# DSS_EDP0_COMMON_0_V2A_CORE_VP_REGS_APB register map
Vendor: Texas Instruments
Registers are 32-bit, access not given, reset 0x0 unless marked. A register's access mark holds for its fields unless they carry their own. Offsets are as the file gives them; [hi:lo] are bit positions; {n}, {i} and the like mark numbered series; 'fields as' and 'values as' point back to an identical list.

## DSS_EDP0_COMMON_0_V2A_CORE_VP_REGS_APB (part 2 of 3)
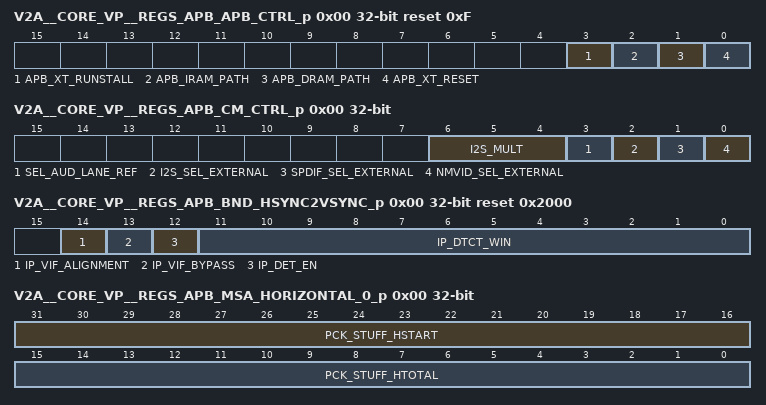
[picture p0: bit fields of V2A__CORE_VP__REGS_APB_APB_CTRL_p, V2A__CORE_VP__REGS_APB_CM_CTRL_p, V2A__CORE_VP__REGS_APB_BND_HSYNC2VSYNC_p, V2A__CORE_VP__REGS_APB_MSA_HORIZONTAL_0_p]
0x00 V2A__CORE_VP__REGS_APB_APB_CTRL_p reset 0xF
  [3] APB_XT_RUNSTALL rw — When 1 stalls the CPU from executing further instructions. This bit must be set HIGH during firmware load.
  [2] APB_IRAM_PATH rw — Unused. Kept RW for software backward compatibility.
  [1] APB_DRAM_PATH rw — Unused. Kept RW for software backward compatibility.
  [0] APB_XT_RESET rw — Internal uCPU reset. Active High. Must be cleared to enable firmware load and normal operation of the uCPU.
0x00 V2A__CORE_VP__REGS_APB_CM_CTRL_p
  [6:4] I2S_MULT rw — Select the division of N value for different I2S TDM configuration
  [3] SEL_AUD_LANE_REF rw — When 1 Select Audio CLK as a reference [HDMI] When 0 Select LANE CLK as a reference [DP]
  [2] I2S_SEL_EXTERNAL rw — When 1 Select external values of NMAUD [N/A] for I2S
  [1] SPDIF_SEL_EXTERNAL rw — When 1 Select external values of NMAUD [N/A] for SPDIF
  [0] NMVID_SEL_EXTERNAL rw — When 1 Select external values of NMVID [N/A]
0x00 V2A__CORE_VP__REGS_APB_CM_CTRL_p
  fields as V2A__CORE_VP__REGS_APB_CM_CTRL_p
0x00 V2A__CORE_VP__REGS_APB_BND_HSYNC2VSYNC_p reset 0x2000
  [14] IP_VIF_ALIGNMENT rw — Alignment of the input pixel data at the pixel interface: 0-MSB alignment 1-LSB alignment.
  [13] IP_VIF_BYPASS rw — Bypass video interface.
  [12] IP_DET_EN rw — Enable detection of Interlace formats after decided if the polarity is Automatic or Manual detection.
  [11:0] IP_DTCT_WIN rw — Bound for HSYNC to VSYNC for all fields.
0x00 V2A__CORE_VP__REGS_APB_MSA_HORIZONTAL_0_p rw
  [31:16] PCK_STUFF_HSTART — MSA Hstart value. Horizontal active start from leading edge of Hsync, measured in pixel count.
  [15:0] PCK_STUFF_HTOTAL — MSA HTotal value. Horizontal total of transmitted main video stream, measured in pixel count.
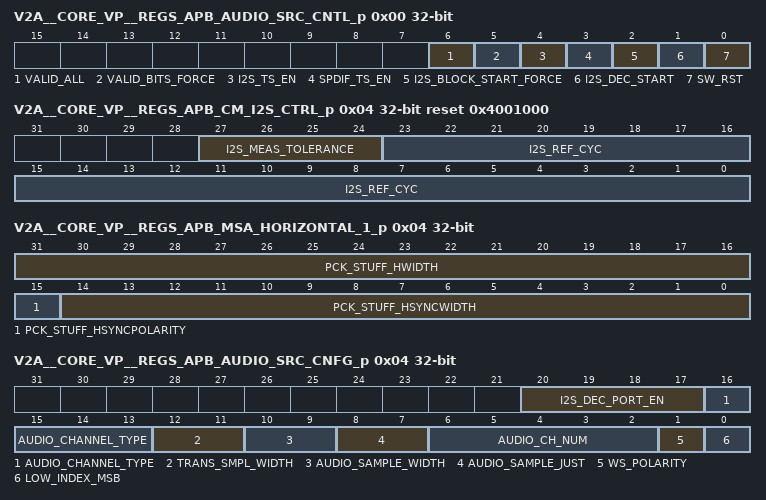
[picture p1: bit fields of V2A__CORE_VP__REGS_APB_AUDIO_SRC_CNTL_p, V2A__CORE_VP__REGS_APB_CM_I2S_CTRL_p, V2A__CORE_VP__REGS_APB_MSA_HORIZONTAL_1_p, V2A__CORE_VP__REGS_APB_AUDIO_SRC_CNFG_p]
0x00 V2A__CORE_VP__REGS_APB_AUDIO_SRC_CNTL_p
  [6] VALID_ALL rw — valid bit for all samples
  [5] VALID_BITS_FORCE rw — Force valid bits of the channels
  [4] I2S_TS_EN rw — Enable I2S Time Stamp when decoders are disabled
  [3] SPDIF_TS_EN rw — Enable SPDIF Time Stamp when decoders are disabled
  [2] I2S_BLOCK_START_FORCE rw — Force a Block Start in the audio stream
  [1] I2S_DEC_START rw — When high Source Decoder starts.
  [0] SW_RST rw — Software reset. Active high.
0x00 V2A__CORE_VP__REGS_APB_SOURCE_PIF_WR_ADDR_p
  [3:0] WR_ADDR rw — 4 MSB of the packet memory address in which the data is written.
0x04 V2A__CORE_VP__REGS_APB_xt_int_ctrl_p
  [1:0] XT_INT_POLARITY rw — Each bit inverts appropriate interrupt signal provided do internal CPU interrupt input.
0x04 V2A__CORE_VP__REGS_APB_CM_I2S_CTRL_p reset 0x4001000
  [27:24] I2S_MEAS_TOLERANCE rw — Measurement tolerance of Audio clock to be stable in clocks
  [23:0] I2S_REF_CYC rw — Reference cycles for I2S Audio meter
0x04 V2A__CORE_VP__REGS_APB_HSYNC2VSYNC_F1_L1_p
  [15:0] IP_DTCT_HSYNC2VSYNC_F1 ro — Value of HSYNC to VSYNC field 1.
0x04 V2A__CORE_VP__REGS_APB_MSA_HORIZONTAL_1_p rw
  [31:16] PCK_STUFF_HWIDTH — MSA Hwidth parameter. Active video width, measured in pixel count.
  [15] PCK_STUFF_HSYNCPOLARITY — MSA HSync Polarity. 0 - Active high pulse. Synchronization signal is high for the sync pulse width. 1 - Active low pulse. Synchronization signal is low for the sync pulse width. This value may be different than actual polarity of the stream received at the video input interface.
  [14:0] PCK_STUFF_HSYNCWIDTH — MSA HSyncWidth parameter. Hsync width, measured in pixel count.
0x04 V2A__CORE_VP__REGS_APB_AUDIO_SRC_CNFG_p
  [20:17] I2S_DEC_PORT_EN rw — Enables the I2S Decoder ports. Allowed values are: 0001 - I2S port 0 is enabled. 0011 - I2S ports 0,1 are enabled. 1111 - I2S ports 0,1,2,3 are enabled. No other values are allowed.
  [16:13] AUDIO_CHANNEL_TYPE rw — Set the transmission type.
  [12:11] TRANS_SMPL_WIDTH rw — Decoder Word Select width: 00-16 bit 01-24 bit 10-32 bit
  [10:9] AUDIO_SAMPLE_WIDTH rw — Decoder sample width: 00-16 bit 01-24 bit 10-32 bit
  [8:7] AUDIO_SAMPLE_JUST rw — Data justification setting: 00 left-justified 01 right-justified
  [6:2] AUDIO_CH_NUM rw — Number of channels to decode
  [1] WS_POLARITY rw — Word Select Polarity. 0: No change 1: Inverted.
  [0] LOW_INDEX_MSB rw — When low MSB is transmitted first. When high LSB is transmitted first.
0x04 V2A__CORE_VP__REGS_APB_SOURCE_PIF_WR_REQ_p
  [0] HOST_WR rw — Write request bit for the host write transaction, active high. Bit is automatically cleared when operation is completed.
0x08 V2A__CORE_VP__REGS_APB_MAILBOX_FULL_ADDR_p
  [0] MAILBOX_FULL ro — Mailbox full indication. 0x1-mailbox full. No more messages can be sent to mailbox 0x0-mailbox not-full. At least 1 write can be performed to mailbox
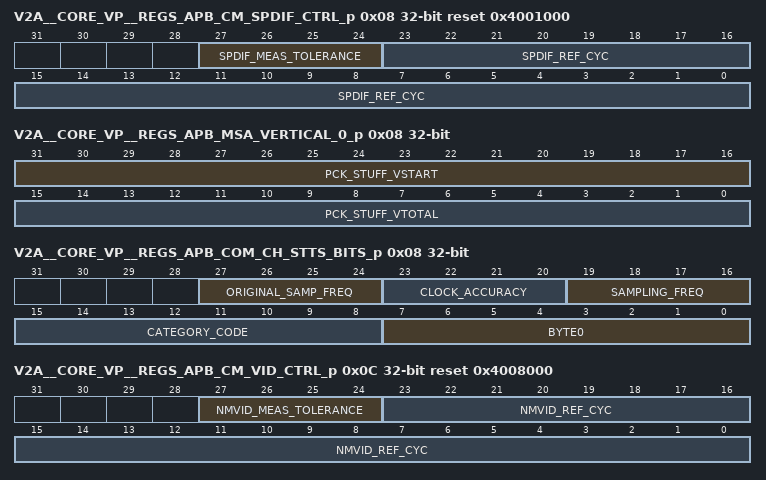
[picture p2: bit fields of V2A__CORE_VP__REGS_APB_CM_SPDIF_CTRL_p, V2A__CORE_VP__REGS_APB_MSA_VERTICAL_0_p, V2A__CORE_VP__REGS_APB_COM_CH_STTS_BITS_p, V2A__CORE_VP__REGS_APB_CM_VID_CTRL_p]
0x08 V2A__CORE_VP__REGS_APB_CM_SPDIF_CTRL_p reset 0x4001000
  [27:24] SPDIF_MEAS_TOLERANCE rw — SPDIF measurement tolerance to be stable in clocks
  [23:0] SPDIF_REF_CYC rw — Reference cycles of SPDIF measurement
0x08 V2A__CORE_VP__REGS_APB_HSYNC2VSYNC_F2_L1_p
  [15:0] IP_DTCT_HSYNC2VSYNC_F2 ro — Value of HSYNC to VSYNC field 2.
0x08 V2A__CORE_VP__REGS_APB_MSA_VERTICAL_0_p rw
  [31:16] PCK_STUFF_VSTART — MSA Vstart parameter. Vertical active start from leading edge of Vsync, measured in line count.
  [15:0] PCK_STUFF_VTOTAL — MSA Vtotal parameter. Vertical total of transmitted main video stream, measured in line count.
0x08 V2A__CORE_VP__REGS_APB_COM_CH_STTS_BITS_p
  [27:24] ORIGINAL_SAMP_FREQ rw — Original Sampling Freq. of transmitted channel. Same for all channels.
  [23:20] CLOCK_ACCURACY rw — Clock Accuracy of transmitted channel. Same for all channels.
  [19:16] SAMPLING_FREQ rw — Sampling Frequency of transmitted channel. Same for all channels.
  [15:8] CATEGORY_CODE rw — Category Code of transmitted channel. Same for all channels.
  [7:0] BYTE0 rw — Byte 0 of transmitted channel. Same for all channels.
0x08 V2A__CORE_VP__REGS_APB_SOURCE_PIF_RD_ADDR_p
  [3:0] RD_ADDR rw — 4 MSB of the packet memory address from which the data is read.
0x0C V2A__CORE_VP__REGS_APB_MAILBOX_EMPTY_ADDR_p reset 0x1
  [0] MAILBOX_EMPTY ro — Mailbox empty indication. 0x1-mailbox empty. No response available 0x0-mailbox not-empty. There is at least 1 byte of a response in mailbox available to read by Host processor
0x0C V2A__CORE_VP__REGS_APB_CM_VID_CTRL_p reset 0x4008000
  [27:24] NMVID_MEAS_TOLERANCE rw — Video measurement tolerance in pixel clock cycles
  [23:0] NMVID_REF_CYC rw — Video Reference cycles
0x0C V2A__CORE_VP__REGS_APB_CM_VID_CTRL_p reset 0x4008000
  fields as V2A__CORE_VP__REGS_APB_CM_VID_CTRL_p
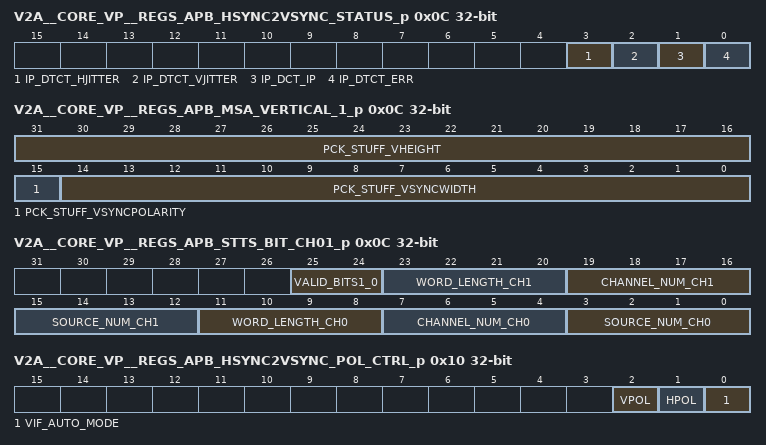
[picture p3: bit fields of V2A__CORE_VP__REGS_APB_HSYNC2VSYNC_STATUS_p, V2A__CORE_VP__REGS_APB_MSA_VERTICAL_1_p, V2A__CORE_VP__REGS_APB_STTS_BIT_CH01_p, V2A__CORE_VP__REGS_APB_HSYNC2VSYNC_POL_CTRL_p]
0x0C V2A__CORE_VP__REGS_APB_HSYNC2VSYNC_STATUS_p
  [3] IP_DTCT_HJITTER ro — Asserted when jitter is observed on htotal i.e. HSYNC rising edge to next HSYNC rising edge delay count. Clear on Read.
  [2] IP_DTCT_VJITTER ro — Asserted when jitter is observed on vtotal i.e. VSYNC rising edge to next VSYNC rising edge delay count. Clear on Read.
  [1] IP_DCT_IP ro — When asserted interlaced format is detected else progressive format.
  [0] IP_DTCT_ERR ro — Asserted when HSYNC to VSYNC bound is violated. Clear on Read.
0x0C V2A__CORE_VP__REGS_APB_MSA_VERTICAL_1_p rw
  [31:16] PCK_STUFF_VHEIGHT — MSA VHeigh parameter. Active video height, measured in line count.
  [15] PCK_STUFF_VSYNCPOLARITY — MSA VSyncPolarity. 0 - Active high pulse. Synchronization signal is high for the sync pulse width. 1 - Active low pulse. Synchronization signal is low for the sync pulse width. This value may be different than actual polarity of the stream received at the video input interface.
  [14:0] PCK_STUFF_VSYNCWIDTH — MSA VSyncWidth parameter. Vsync width, measured in line count.
0x0C V2A__CORE_VP__REGS_APB_STTS_BIT_CH01_p
  [25:24] VALID_BITS1_0 rw — Valid Bits for channel 1 and 0 if force is enabled
  [23:20] WORD_LENGTH_CH1 rw — Channel 1 word length.
  [19:16] CHANNEL_NUM_CH1 rw — Channel 1 channel number.
  [15:12] SOURCE_NUM_CH1 rw — Channel 1 Source number.
  [11:8] WORD_LENGTH_CH0 rw — Channel 0 word length.
  [7:4] CHANNEL_NUM_CH0 rw — Channel 0 channel number.
  [3:0] SOURCE_NUM_CH0 rw — Channel 0 Source number.
0x0C V2A__CORE_VP__REGS_APB_SOURCE_PIF_RD_REQ_p
  [0] HOST_RD rw — Read request bit for the host read transaction, active high. Bit is automatically cleared when operation is completed.
0x10 V2A__CORE_VP__REGS_APB_mailbox0_wr_data_p
  [7:0] MAILBOX0_WR_DATA rw — Mailbox write data.
0x10 V2A__CORE_VP__REGS_APB_CM_LANE_CTRL_p
  [23:0] LANE_REF_CYC rw — Reference cycles when using lane clock as Reference [DP]
0x10 V2A__CORE_VP__REGS_APB_HSYNC2VSYNC_POL_CTRL_p
  [2] VPOL rw — VSYNC polarity: 0-active HIGH 1-active LOW.
  [1] HPOL rw — HSYNC polarity: 0-active HIGH 1-active LOW.
  [0] VIF_AUTO_MODE rw — Automatic or Manual configuration of the polarity: 0-vpol and hpol settings are used 1-automatic detection of polarity of input VSYNC and HSYNC
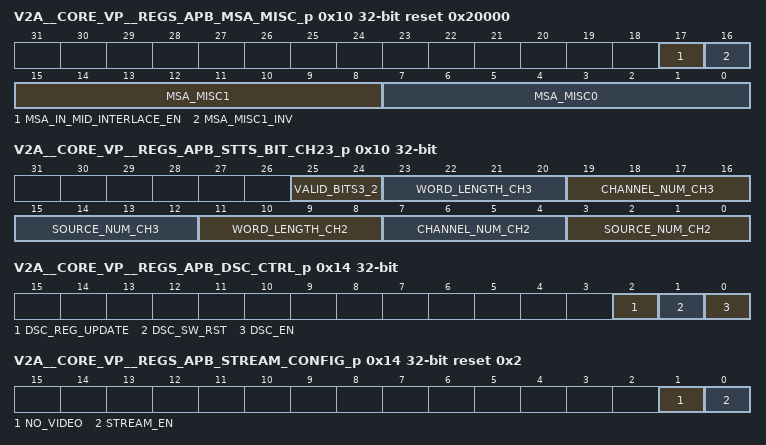
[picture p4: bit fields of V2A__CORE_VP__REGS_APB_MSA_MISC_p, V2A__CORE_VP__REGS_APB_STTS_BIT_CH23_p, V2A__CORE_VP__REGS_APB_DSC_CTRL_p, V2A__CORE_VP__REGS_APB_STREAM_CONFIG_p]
0x10 V2A__CORE_VP__REGS_APB_MSA_MISC_p reset 0x20000
  [17] MSA_IN_MID_INTERLACE_EN rw — MSA transmission control in interlaced mode. 0 - enable transmission of MSA on each field, 1 - MSA transmitted on Top only
  [16] MSA_MISC1_INV rw — L/R toggle for interlaced and field sequential video. 0 - left 1 - right
  [15:8] MSA_MISC1 rw — MAS Miscellaneous1 as described in DisplayPort specification.
  [7:0] MSA_MISC0 rw — MSA Miscellaneous0 as described in DisplayPort specification.
0x10 V2A__CORE_VP__REGS_APB_STTS_BIT_CH23_p
  [25:24] VALID_BITS3_2 rw — Valid Bits for channel 3 and 2 if force is enabled
  [23:20] WORD_LENGTH_CH3 rw — Channel 3 word length.
  [19:16] CHANNEL_NUM_CH3 rw — Channel 3 channel number.
  [15:12] SOURCE_NUM_CH3 rw — Channel 3 Source number.
  [11:8] WORD_LENGTH_CH2 rw — Channel 2 word length.
  [7:4] CHANNEL_NUM_CH2 rw — Channel 2 channel number.
  [3:0] SOURCE_NUM_CH2 rw — Channel 2 Source number.
0x10 V2A__CORE_VP__REGS_APB_SOURCE_PIF_DATA_WR_p rw
  [31:0] DATA_WR — The 32 bits of the data to be written to the packet memory. When written to this register fifo1_wr_enable will automatically be asserted and the data is stored in FIFO.
0x14 V2A__CORE_VP__REGS_APB_mailbox0_rd_data_p
  [7:0] MAILBOX0_RD_DATA ro — Mailbox Read data.
0x14 V2A__CORE_VP__REGS_APB_I2S_NM_STABLE_p
  [0] I2S_MNAUD_STABLE ro — I2S NMAUD Mesurment stable
0x14 V2A__CORE_VP__REGS_APB_DSC_CTRL_p
  [2] DSC_REG_UPDATE rw — DSC registers update: active HIGH.
  [1] DSC_SW_RST rw — DSC software reset: active HIGH.
  [0] DSC_EN rw — DSC enable bit: 1-DSC is enabled 0-DSC is disabled
0x14 V2A__CORE_VP__REGS_APB_STREAM_CONFIG_p reset 0x2
  [1] NO_VIDEO rw — Stream no video mode. 0 - video mode 1 - no video mode
  [0] STREAM_EN rw — Stream enable. 0 - stream disabled 1 - stream enabled
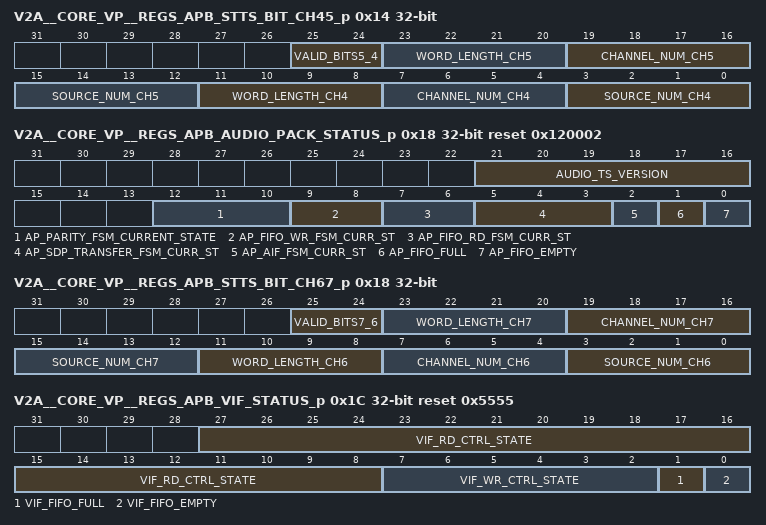
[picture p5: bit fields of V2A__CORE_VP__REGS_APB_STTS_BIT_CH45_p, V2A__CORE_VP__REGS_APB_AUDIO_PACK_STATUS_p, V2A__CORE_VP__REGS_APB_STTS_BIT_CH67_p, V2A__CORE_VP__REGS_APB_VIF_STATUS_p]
0x14 V2A__CORE_VP__REGS_APB_STTS_BIT_CH45_p
  [25:24] VALID_BITS5_4 rw — Valid Bits for channel 5 and 4 if force is enabled
  [23:20] WORD_LENGTH_CH5 rw — Channel 5 word length.
  [19:16] CHANNEL_NUM_CH5 rw — Channel 5 channel number.
  [15:12] SOURCE_NUM_CH5 rw — Channel 5 Source number.
  [11:8] WORD_LENGTH_CH4 rw — Channel 4 word length.
  [7:4] CHANNEL_NUM_CH4 rw — Channel 4 channel number.
  [3:0] SOURCE_NUM_CH4 rw — Channel 4 Source number.
0x14 V2A__CORE_VP__REGS_APB_SOURCE_PIF_DATA_RD_p ro
  [31:0] FIFO2_DATA_OUT — The 32 bits of the data to be read from the packet memory. When read from this register fifo2_rd_enable will automatically be asserted and the data is read from the FIFO.
0x18 V2A__CORE_VP__REGS_APB_KEEP_ALIVE_p
  [7:0] KEEP_ALIVE_CNT ro — Software keep alive counter. Counter is initialized to 0x0 after reset and incremented by 0x1 with every FW kernel loop. It can be used to determine if internal CPU started running correctly.
0x18 V2A__CORE_VP__REGS_APB_I2S_NCTS_STABLE_p
  [0] I2S_NCTS_STABLE ro — i2s CTS measurement stable
0x18 V2A__CORE_VP__REGS_APB_AUDIO_PACK_STATUS_p reset 0x120002
  [21:16] AUDIO_TS_VERSION rw — Audio timestamp version. This field is transmitted in HB3[7:2] of a Audio_TimeStamp SDP Header.
  [12:10] AP_PARITY_FSM_CURRENT_STATE ro — Audio pack parity calc fsm state. Used only for debug purposes.
  [9:8] AP_FIFO_WR_FSM_CURR_ST ro — Audio pack FIFO write fsm state. Used only for debug purposes.
  [7:6] AP_FIFO_RD_FSM_CURR_ST ro — Audio pack FIFO read fsm state. Used only for debug purposes.
  [5:3] AP_SDP_TRANSFER_FSM_CURR_ST ro — Audio pack sdp transfer fsm state. Used only for debug purposes.
  [2] AP_AIF_FSM_CURR_ST ro — Audio pack aif fsm state. Used only for debug purposes.
  [1] AP_FIFO_FULL ro — Audio Pack Sync FIFO full flag, active high. Used only for debug purposes.
  [0] AP_FIFO_EMPTY ro — Audio Pack Sync FIFO empty flag, active high. Used only for debug purposes.
0x18 V2A__CORE_VP__REGS_APB_STTS_BIT_CH67_p
  [25:24] VALID_BITS7_6 rw — Valid Bits for channel 7 and 6 if force is enabled
  [23:20] WORD_LENGTH_CH7 rw — Channel 7 word length.
  [19:16] CHANNEL_NUM_CH7 rw — Channel 7 channel number.
  [15:12] SOURCE_NUM_CH7 rw — Channel 7 Source number.
  [11:8] WORD_LENGTH_CH6 rw — Channel 6 word length.
  [7:4] CHANNEL_NUM_CH6 rw — Channel 6 channel number.
  [3:0] SOURCE_NUM_CH6 rw — Channel 6 Source number.
0x18 V2A__CORE_VP__REGS_APB_SOURCE_PIF_FIFO1_FLUSH_p
  [0] FIFO1_FLUSH rw — Fifo1 flush bit, active high. Bit is automatically cleared when operation is completed.
0x1C V2A__CORE_VP__REGS_APB_VER_L_p
  [7:0] VER_LSB ro — Software Version lower byte. Loaded by Firmware at the beginning of firmware operation.
0x1C V2A__CORE_VP__REGS_APB_SPDIF_NM_STABLE_p
  [0] SPDIF_MNAUD_STABLE ro — SPDIF NMAUD measurement stable
0x1C V2A__CORE_VP__REGS_APB_VIF_STATUS_p reset 0x5555
  [27:8] VIF_RD_CTRL_STATE ro — VIF rd fsm current state.
  [7:2] VIF_WR_CTRL_STATE ro — VIF wr fsm current state.
  [1] VIF_FIFO_FULL ro — VIF ASync FIFO full flag, active high.
  [0] VIF_FIFO_EMPTY ro — VIF ASync FIFO empty flag, active high.
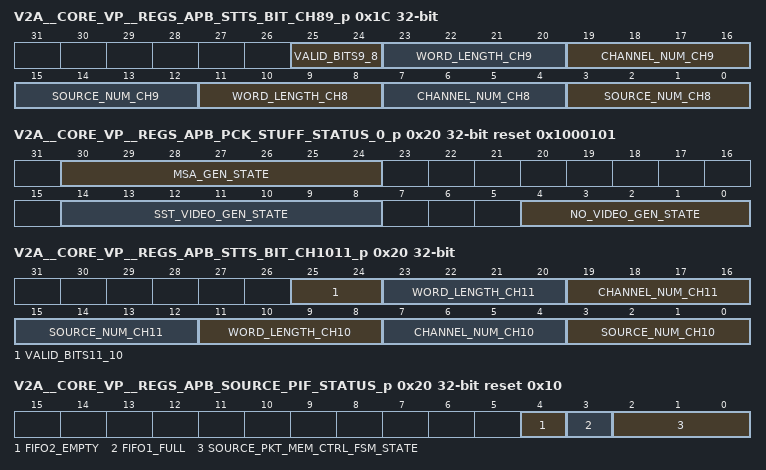
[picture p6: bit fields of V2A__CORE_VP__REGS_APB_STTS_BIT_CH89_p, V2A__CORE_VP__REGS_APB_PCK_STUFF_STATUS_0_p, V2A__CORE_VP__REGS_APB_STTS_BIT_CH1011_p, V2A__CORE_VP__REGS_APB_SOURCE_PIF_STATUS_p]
0x1C V2A__CORE_VP__REGS_APB_STTS_BIT_CH89_p
  [25:24] VALID_BITS9_8 rw — Valid Bits for channel 9 and 8 if force is enabled
  [23:20] WORD_LENGTH_CH9 rw — Channel 9 word length.
  [19:16] CHANNEL_NUM_CH9 rw — Channel 9 channel number.
  [15:12] SOURCE_NUM_CH9 rw — Channel 9 Source number.
  [11:8] WORD_LENGTH_CH8 rw — Channel 8 word length.
  [7:4] CHANNEL_NUM_CH8 rw — Channel 8 channel number.
  [3:0] SOURCE_NUM_CH8 rw — Channel 8 Source number.
0x1C V2A__CORE_VP__REGS_APB_SOURCE_PIF_FIFO2_FLUSH_p
  [0] FIFO2_FLUSH rw — Fifo2 flush bit, active high. Bit is automatically cleared when operation is completed.
0x20 V2A__CORE_VP__REGS_APB_VER_H_p
  [7:0] VER_MSB ro — Software Version higher byte. Loaded by Firmware at the beginning of firmware operation.
0x20 V2A__CORE_VP__REGS_APB_SPDIF_NCTS_STABLE_p
  [0] SPDIF_NCTS_STABLE ro — SPDIF CTS measurement stable
0x20 V2A__CORE_VP__REGS_APB_PCK_STUFF_STATUS_0_p reset 0x1000101
  [30:24] MSA_GEN_STATE ro — Secondary Data generator FSM status.
  [14:8] SST_VIDEO_GEN_STATE ro — SST video generator FSM status.
  [4:0] NO_VIDEO_GEN_STATE ro — No video generator FSM status.
0x20 V2A__CORE_VP__REGS_APB_STTS_BIT_CH1011_p
  [25:24] VALID_BITS11_10 rw — Valid Bits for channel 11 and 10 if force is enabled
  [23:20] WORD_LENGTH_CH11 rw — Channel 11 word length.
  [19:16] CHANNEL_NUM_CH11 rw — Channel 11 channel number.
  [15:12] SOURCE_NUM_CH11 rw — Channel 11 Source number.
  [11:8] WORD_LENGTH_CH10 rw — Channel 10 word length.
  [7:4] CHANNEL_NUM_CH10 rw — Channel 10 channel number.
  [3:0] SOURCE_NUM_CH10 rw — Channel 10 Source number.
0x20 V2A__CORE_VP__REGS_APB_SOURCE_PIF_STATUS_p reset 0x10
  [4] FIFO2_EMPTY ro — Fifo2 empty indication, when high indicates that FIFO2 is empty
  [3] FIFO1_FULL ro — Fifo1 full indication, when high indicates that FIFO1 is full
  [2:0] SOURCE_PKT_MEM_CTRL_FSM_STATE ro — State of the FSM that controls packet memory transactions.
0x24 V2A__CORE_VP__REGS_APB_VER_LIB_L_ADDR_p
  [7:0] SW_LIB_VER_L ro — Software Library Version lower byte. Loaded by Firmware at the beginning of firmware operation.
0x24 V2A__CORE_VP__REGS_APB_NMVID_MEAS_STABLE_p
  [0] ST_NMVID_MEAS_STABLE ro — Pixel clock NMVID measurement stable
0x24 V2A__CORE_VP__REGS_APB_NMVID_MEAS_STABLE_p
  [0] ST_NMVID_MEAS_STABLE ro — Pixel clock NMVID measurement stable
0x24 V2A__CORE_VP__REGS_APB_PCK_STUFF_STATUS_1_p reset 0x1
  [5:0] SST_SS_GEN_STATE ro — MSA generator FSM status.
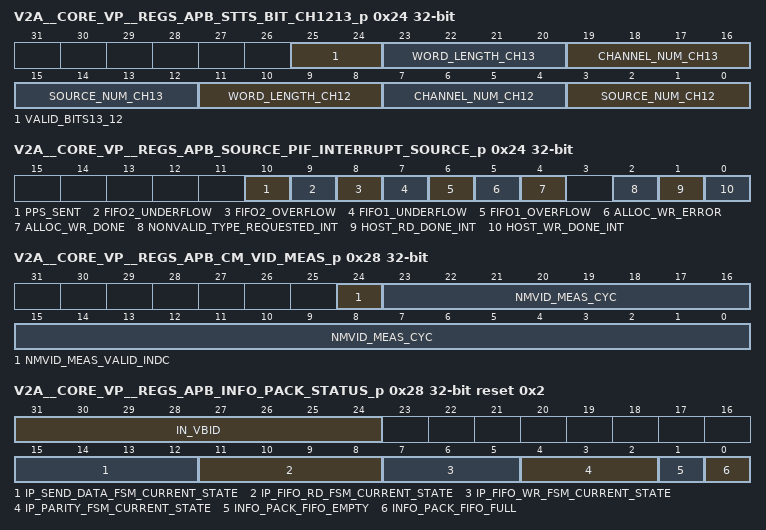
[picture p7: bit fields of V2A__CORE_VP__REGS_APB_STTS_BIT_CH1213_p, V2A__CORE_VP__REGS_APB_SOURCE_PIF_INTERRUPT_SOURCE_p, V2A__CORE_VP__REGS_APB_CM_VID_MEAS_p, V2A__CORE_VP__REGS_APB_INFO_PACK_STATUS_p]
0x24 V2A__CORE_VP__REGS_APB_STTS_BIT_CH1213_p
  [25:24] VALID_BITS13_12 rw — Valid Bits for channel 13 and 12 if force is enabled
  [23:20] WORD_LENGTH_CH13 rw — Channel 13 word length.
  [19:16] CHANNEL_NUM_CH13 rw — Channel 13 channel number.
  [15:12] SOURCE_NUM_CH13 rw — Channel 13 Source number.
  [11:8] WORD_LENGTH_CH12 rw — Channel 12 word length.
  [7:4] CHANNEL_NUM_CH12 rw — Channel 12 channel number.
  [3:0] SOURCE_NUM_CH12 rw — Channel 12 Source number.
0x24 V2A__CORE_VP__REGS_APB_SOURCE_PIF_INTERRUPT_SOURCE_p
  [10] PPS_SENT ro — PPS sent to framer indication. Active HIGH. Clear on read.
  [9] FIFO2_UNDERFLOW ro — Fifo2 underflow indication. Indicates incorrect programming sequence. Active HIGH. Clear on read.
  [8] FIFO2_OVERFLOW ro — Fifo2 overflow indication. Indicates incorrect programming sequence. Active HIGH. Clear on read.
  [7] FIFO1_UNDERFLOW ro — Fifo1 underflow indication. Indicates incorrect programming sequence. Active HIGH. Clear on read.
  [6] FIFO1_OVERFLOW ro — Fifo1 overflow indication. Indicates incorrect programming sequence. Active HIGH. Clear on read.
  [5] ALLOC_WR_ERROR ro — Error happened, invalid write to the allocation table. Indicates incorrect programming sequence. Active HIGH. Clear on read.
  [4] ALLOC_WR_DONE ro — Successful write to the allocation table. Active HIGH. Clear on read.
  [2] NONVALID_TYPE_REQUESTED_INT ro — Indication that nonvalid type of packet is requested by the packet interface. Indicates incorrect programming sequence. Active HIGH. Clear on read.
  [1] HOST_RD_DONE_INT ro — Indication that the host read transaction finished. Active HIGH. Clear on read.
  [0] HOST_WR_DONE_INT ro — Indication that the host write transaction finished. Active HIGH. Clear on read.
0x28 V2A__CORE_VP__REGS_APB_VER_LIB_H_ADDR_p
  [7:0] SW_LIB_VER_H ro — Software Library Version higher byte. Loaded by Firmware at the beginning of firmware operation.
0x28 V2A__CORE_VP__REGS_APB_CM_VID_MEAS_p
  [24] NMVID_MEAS_VALID_INDC rw — When Toggle Valid pulse is generated to sample MNVID fix value
  [23:0] NMVID_MEAS_CYC rw — Fixed Value for NVID , The MVID is nmvid_ref_cyc[23:0]
0x28 V2A__CORE_VP__REGS_APB_CM_VID_MEAS_p
  fields as V2A__CORE_VP__REGS_APB_CM_VID_MEAS_p
0x28 V2A__CORE_VP__REGS_APB_INFO_PACK_STATUS_p reset 0x2
  [31:24] IN_VBID ro — Value of the sent VB-ID [vb_id_final].
  [15:12] IP_SEND_DATA_FSM_CURRENT_STATE ro — State of the send_data FSM.
  [11:8] IP_FIFO_RD_FSM_CURRENT_STATE ro — State of the fifo_rd FSM.
  [7:5] IP_FIFO_WR_FSM_CURRENT_STATE ro — State of the fifo_wr FSM.
  [4:2] IP_PARITY_FSM_CURRENT_STATE ro — State of the parity FSM.
  [1] INFO_PACK_FIFO_EMPTY ro — Info_pack fifo empty flag, active high.
  [0] INFO_PACK_FIFO_FULL ro — Info_pack fifo full flag, active high.
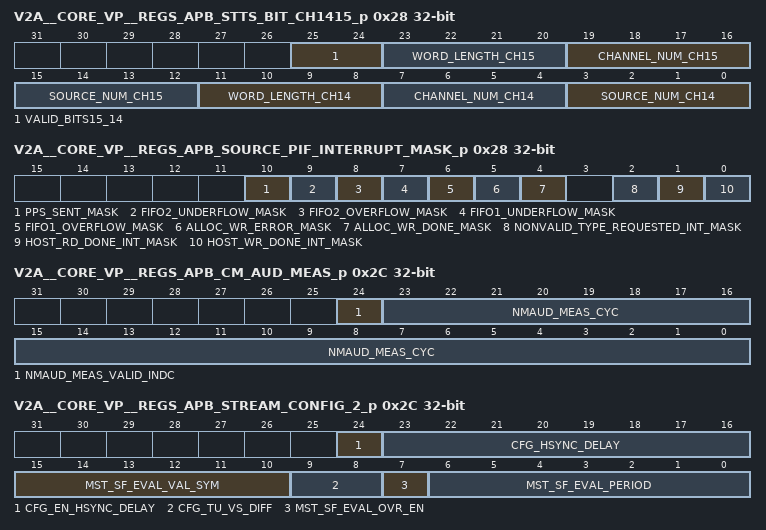
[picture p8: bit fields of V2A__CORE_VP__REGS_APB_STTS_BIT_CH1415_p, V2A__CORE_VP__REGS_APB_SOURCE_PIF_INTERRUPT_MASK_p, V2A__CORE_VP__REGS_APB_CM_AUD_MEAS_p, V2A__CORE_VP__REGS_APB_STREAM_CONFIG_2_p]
0x28 V2A__CORE_VP__REGS_APB_STTS_BIT_CH1415_p
  [25:24] VALID_BITS15_14 rw — Valid Bits for channel 15 and 14 if force is enabled
  [23:20] WORD_LENGTH_CH15 rw — Channel 15 word length.
  [19:16] CHANNEL_NUM_CH15 rw — Channel 15 channel number.
  [15:12] SOURCE_NUM_CH15 rw — Channel 15 Source number.
  [11:8] WORD_LENGTH_CH14 rw — Channel 14 word length.
  [7:4] CHANNEL_NUM_CH14 rw — Channel 14 channel number.
  [3:0] SOURCE_NUM_CH14 rw — Channel 14 Source number.
0x28 V2A__CORE_VP__REGS_APB_SOURCE_PIF_INTERRUPT_MASK_p
  [10] PPS_SENT_MASK rw — Masks the pps_sent interrupt. 0x0-interrupt enabled 0x1-interrupt disabled
  [9] FIFO2_UNDERFLOW_MASK rw — Masks the fifo2_underflow interrupt. 0x0-interrupt enabled 0x1-interrupt disabled
  [8] FIFO2_OVERFLOW_MASK rw — Masks the fifo2_overflow interrupt. 0x0-interrupt enabled 0x1-interrupt disabled
  [7] FIFO1_UNDERFLOW_MASK rw — Masks the fifo1_underflow interrupt. 0x0-interrupt enabled 0x1-interrupt disabled
  [6] FIFO1_OVERFLOW_MASK rw — Masks the fifo1_overflow interrupt. 0x0-interrupt enabled 0x1-interrupt disabled
  [5] ALLOC_WR_ERROR_MASK rw — Masks the alloc_wr_error interrupt. 0x0-interrupt enabled 0x1-interrupt disabled
  [4] ALLOC_WR_DONE_MASK rw — Masks the alloc_wr_done interrupt. 0x0-interrupt enabled 0x1-interrupt disabled
  [2] NONVALID_TYPE_REQUESTED_INT_MASK rw — Masks the nonvalid_type_requested_int interrupt. 0x0-interrupt enabled 0x1-interrupt disabled
  [1] HOST_RD_DONE_INT_MASK rw — Masks the host_rd_done_int interrupt. 0x0-interrupt enabled 0x1-interrupt disabled
  [0] HOST_WR_DONE_INT_MASK rw — Masks the host_wr_done_int interrupt. 0x0-interrupt enabled 0x1-interrupt disabled
0x2C V2A__CORE_VP__REGS_APB_SW_DEBUG_L_p
  [7:0] SW_DEBUG_7_0 ro — Register used for debug purposes [lower byte]. Can be written internally by firmware to allow Core Driver to read the internal status. Not used during normal operation since it requires a special version of firmware with a debug capabilities.
0x2C V2A__CORE_VP__REGS_APB_CM_AUD_MEAS_p
  [24] NMAUD_MEAS_VALID_INDC rw — When Toggle Valid pulse is generated to sample MNAUD fix value
  [23:0] NMAUD_MEAS_CYC rw — Fixed Value for NAUD, The MAUD is lane_ref_cyc[23:0]
0x2C V2A__CORE_VP__REGS_APB_STREAM_CONFIG_2_p
  [24] CFG_EN_HSYNC_DELAY rw — Unused. Kept RW for software backward compatibility.
  [23:16] CFG_HSYNC_DELAY rw — Unused. Kept RW for software backward compatibility.
  [15:10] MST_SF_EVAL_VAL_SYM rw — Number of valid symbols to output during stream fill evaluation period. This should be less than mst_sf_eval_period.
  [9:8] CFG_TU_VS_DIFF rw — Unused. Kept RW for software backward compatibility.
  [7] MST_SF_EVAL_OVR_EN rw — Enable override of mst_sf_eval_period, mst_sf_eval_val_sym and cfg_tu_vs_diff when in MST mode.
  [6:0] MST_SF_EVAL_PERIOD rw — Stream fill evaluation period when in MST mode and mst_sf_eval_ovr_en bit is set.
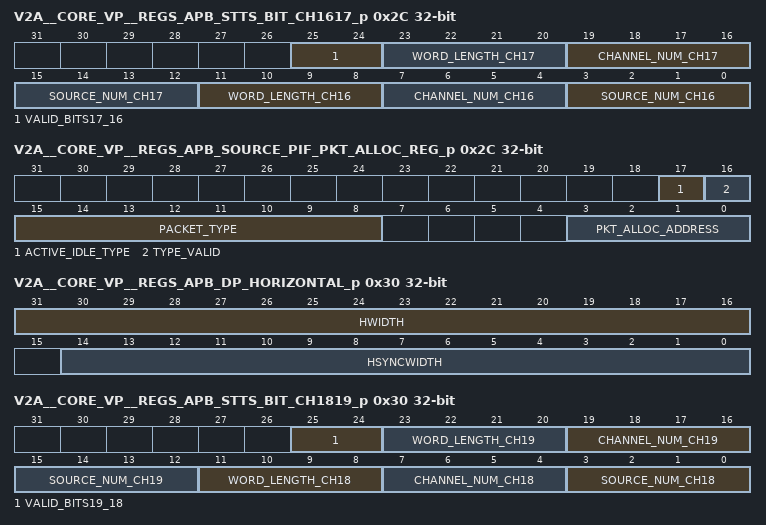
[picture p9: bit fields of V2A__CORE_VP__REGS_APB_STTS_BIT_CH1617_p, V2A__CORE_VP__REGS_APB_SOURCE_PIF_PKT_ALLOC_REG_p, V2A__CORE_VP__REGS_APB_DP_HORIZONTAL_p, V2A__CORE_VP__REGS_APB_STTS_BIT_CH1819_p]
0x2C V2A__CORE_VP__REGS_APB_STTS_BIT_CH1617_p
  [25:24] VALID_BITS17_16 rw — Valid Bits for channel 17 and 16 if force is enabled
  [23:20] WORD_LENGTH_CH17 rw — Channel 17 word length.
  [19:16] CHANNEL_NUM_CH17 rw — Channel 17 channel number.
  [15:12] SOURCE_NUM_CH17 rw — Channel 17 Source number.
  [11:8] WORD_LENGTH_CH16 rw — Channel 16 word length.
  [7:4] CHANNEL_NUM_CH16 rw — Channel 16 channel number.
  [3:0] SOURCE_NUM_CH16 rw — Channel 16 Source number.
0x2C V2A__CORE_VP__REGS_APB_SOURCE_PIF_PKT_ALLOC_REG_p
  [17] ACTIVE_IDLE_TYPE rw — Indicates in which mode the SDP will be sent. 0- no_video mode, 1- video mode
  [16] TYPE_VALID rw — 1 for valid, 0 for nonvalid
  [15:8] PACKET_TYPE rw — 8-bit value of the packet type
  [3:0] PKT_ALLOC_ADDRESS rw — Address of the register in the source allocation table
0x30 V2A__CORE_VP__REGS_APB_SW_DEBUG_H_p
  [7:0] SW_DEBUG_15_8 ro — Register used for debug purposes [higher byte]. Can be written internally by firmware to allow Core Driver to read the internal status. Not used during normal operation since it requires a special version of firmware with a debug capabilities.
0x30 V2A__CORE_VP__REGS_APB_I2S_MEAS_p
  [23:0] I2_MEAS ro — I2S measurement value
0x30 V2A__CORE_VP__REGS_APB_DP_HORIZONTAL_p
  [31:16] HWIDTH rw — Horizontal Active Video Width. Width of video active period [VACTIVE] expressed in number pixel clock cycles. It must be a multiply of 16.
  [14:0] HSYNCWIDTH rw — Horizontal Sync Width. Width of horizontal synchronization pulse [HSYNC] expressed in number pixel clock cycles.
0x30 V2A__CORE_VP__REGS_APB_STTS_BIT_CH1819_p
  [25:24] VALID_BITS19_18 rw — Valid Bits for channel 19 and 18 if force is enabled
  [23:20] WORD_LENGTH_CH19 rw — Channel 19 word length.
  [19:16] CHANNEL_NUM_CH19 rw — Channel 19 channel number.
  [15:12] SOURCE_NUM_CH19 rw — Channel 19 Source number.
  [11:8] WORD_LENGTH_CH18 rw — Channel 18 word length.
  [7:4] CHANNEL_NUM_CH18 rw — Channel 18 channel number.
  [3:0] SOURCE_NUM_CH18 rw — Channel 18 Source number.
0x30 V2A__CORE_VP__REGS_APB_SOURCE_PIF_PKT_ALLOC_WR_EN_p
  [0] PKT_ALLOC_WR_EN rw — Enable bit for writing to the allocation table, active high
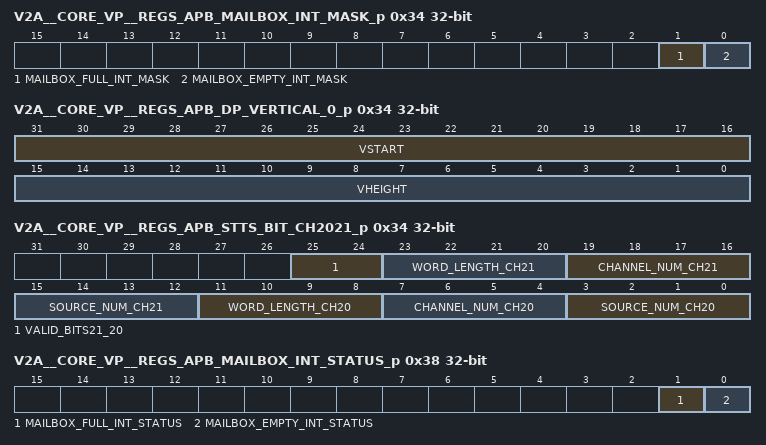
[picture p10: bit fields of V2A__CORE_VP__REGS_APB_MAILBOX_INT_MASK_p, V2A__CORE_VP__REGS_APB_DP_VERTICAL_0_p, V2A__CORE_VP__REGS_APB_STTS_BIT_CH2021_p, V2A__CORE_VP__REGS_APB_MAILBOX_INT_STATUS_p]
0x34 V2A__CORE_VP__REGS_APB_MAILBOX_INT_MASK_p
  [1] MAILBOX_FULL_INT_MASK rw — Mailbox Full Interrupt mask 0x0-interrupt enabled 0x1-interrupt disabled
  [0] MAILBOX_EMPTY_INT_MASK rw — Mailbox Not-empty Interrupt mask 0x0-interrupt enabled 0x1-interrupt disabled
0x34 V2A__CORE_VP__REGS_APB_SPDIF_MEAS_p
  [23:0] SPDIF_MEAS ro — SPDIF Clock Meter measurement value [in DP]
0x34 V2A__CORE_VP__REGS_APB_DP_VERTICAL_0_p rw
  [31:16] VSTART — Vertical Active Start [VSTART]. Index of the first active line in a video frame.
  [15:0] VHEIGHT — Vertical Active High [VACTIVE]. Number of active lines in a video frame.
0x34 V2A__CORE_VP__REGS_APB_STTS_BIT_CH2021_p
  [25:24] VALID_BITS21_20 rw — Valid Bits for channel 21 and 20 if force is enabled
  [23:20] WORD_LENGTH_CH21 rw — Channel 21 word length.
  [19:16] CHANNEL_NUM_CH21 rw — Channel 21 channel number.
  [15:12] SOURCE_NUM_CH21 rw — Channel 21 Source number.
  [11:8] WORD_LENGTH_CH20 rw — Channel 20 word length.
  [7:4] CHANNEL_NUM_CH20 rw — Channel 20 channel number.
  [3:0] SOURCE_NUM_CH20 rw — Channel 20 Source number.
0x34 V2A__CORE_VP__REGS_APB_SOURCE_PIF_SW_RESET_p
  [0] SW_RST rw — Software reset, active high. Bit is automatically cleared when operation is completed.
0x38 V2A__CORE_VP__REGS_APB_MAILBOX_INT_STATUS_p
  [1] MAILBOX_FULL_INT_STATUS ro — Mailbox full interrupt. Active HIGH. Cleared on read. This interrupt is set when mailbox becomes full which means there is no more space for messages sent from Host processor to internal uCPU and when this interrupt is enabled in MAILBOX_INT_MASK_p register. It is set when mailbox_full bit transitions from 0 to 1.
  [0] MAILBOX_EMPTY_INT_STATUS ro — Mailbox not-empty interrupt. Active HIGH. Cleared on read. This interrupt is set when mailbox becomes not-empty which means there is a response in the mailbox available to read by the Host processer and when interrupt is enabled in MAILBOX_INT_MASK_p register. It is set when mailbox_empty bit transitions from 1 to 0.
0x38 V2A__CORE_VP__REGS_APB_NMVID_MEAS_p
  [23:0] NMVID_MEAS ro — Video clock measurement value
0x38 V2A__CORE_VP__REGS_APB_NMVID_MEAS_p
  [23:0] NMVID_MEAS ro — Video clock measurement value
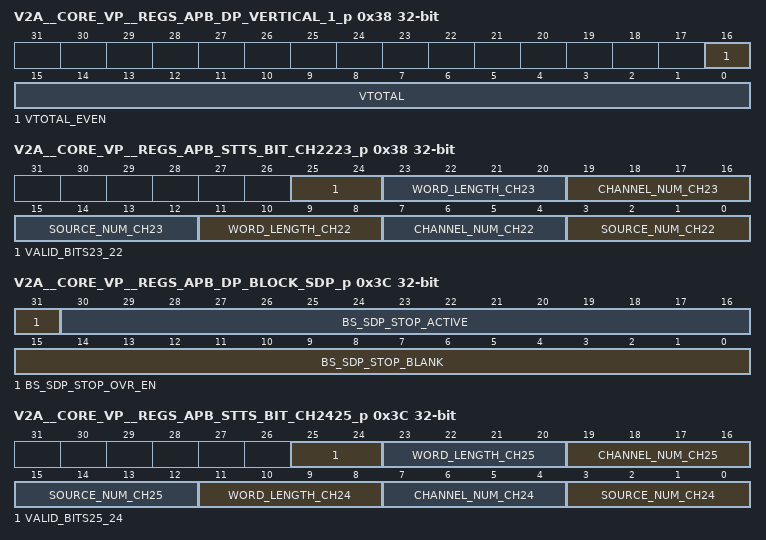
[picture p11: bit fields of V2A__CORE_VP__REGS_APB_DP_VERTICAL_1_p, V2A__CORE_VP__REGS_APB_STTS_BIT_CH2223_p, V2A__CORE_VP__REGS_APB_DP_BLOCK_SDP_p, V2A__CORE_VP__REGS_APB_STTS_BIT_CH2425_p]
0x38 V2A__CORE_VP__REGS_APB_DP_VERTICAL_1_p
  [16] VTOTAL_EVEN rw — Indicate Vtotal is an even number as described in MISC1[0] in DisplayPort specification. Active high.
  [15:0] VTOTAL rw — Vertical Total Heigh [HTOTAL]. Total number of lines per frame.
0x38 V2A__CORE_VP__REGS_APB_STTS_BIT_CH2223_p
  [25:24] VALID_BITS23_22 rw — Valid Bits for channel 23 and 22 if force is enabled
  [23:20] WORD_LENGTH_CH23 rw — Channel 23 word length.
  [19:16] CHANNEL_NUM_CH23 rw — Channel 23 channel number.
  [15:12] SOURCE_NUM_CH23 rw — Channel 23 Source number.
  [11:8] WORD_LENGTH_CH22 rw — Channel 22 word length.
  [7:4] CHANNEL_NUM_CH22 rw — Channel 22 channel number.
  [3:0] SOURCE_NUM_CH22 rw — Channel 22 Source number.
0x38 V2A__CORE_VP__REGS_APB_SOURCE_PIF_PPS_HEADER_p rw
  [31:0] PPS_HEADER — value of the PPS header as per DPv1.4
0x3C V2A__CORE_VP__REGS_APB_SW_CLK_L_p
  [7:0] SW_CLOCK_VAL_L rw — Fractional of the clock decimal value. Should be loaded by API to the value that reflects the frequency of clock provided to core clock input.
0x3C V2A__CORE_VP__REGS_APB_DP_BLOCK_SDP_p rw
  [31] BS_SDP_STOP_OVR_EN — Enable override settings. If this bit is not set, the hardware will not automatically block SDP transmission during video lines, this may result in shifting of video timing.
  [30:16] BS_SDP_STOP_ACTIVE — Block SDP scheduling after specified cycles after BS during horizontal blank lines. Maximum is 32767. If set to 0, no SDPs will be transmitted during hblank. Only used when bs_sdp_stop_ovr_en is set to 1.
  [15:0] BS_SDP_STOP_BLANK — Block SDP scheduling after specified cycles after BS during vertical blank lines. Maximum is 65535. If set to 0, no SDPs will be transmitted during vblank. Only used when bs_sdp_stop_ovr_en is set to 1.
0x3C V2A__CORE_VP__REGS_APB_STTS_BIT_CH2425_p
  [25:24] VALID_BITS25_24 rw — Valid Bits for channel 25 and 24 if force is enabled
  [23:20] WORD_LENGTH_CH25 rw — Channel 25 word length.
  [19:16] CHANNEL_NUM_CH25 rw — Channel 25 channel number.
  [15:12] SOURCE_NUM_CH25 rw — Channel 25 Source number.
  [11:8] WORD_LENGTH_CH24 rw — Channel 24 word length.
  [7:4] CHANNEL_NUM_CH24 rw — Channel 24 channel number.
  [3:0] SOURCE_NUM_CH24 rw — Channel 24 Source number.
0x3C V2A__CORE_VP__REGS_APB_SOURCE_PIF_PPS_p
  [0] PPS rw — PPS SDP indication, active high. When set, the SDP to be read/written from/to the memory by the host is in fact PPS. Bit is automatically cleared when operation is completed.
0x40 V2A__CORE_VP__REGS_APB_SW_CLK_H_p reset 0x64
  [7:0] SW_CLOCK_VAL_H rw — Clock frequency in decimal values. Should be loaded by API to the value that reflects the frequency of clock provided to core clock input.
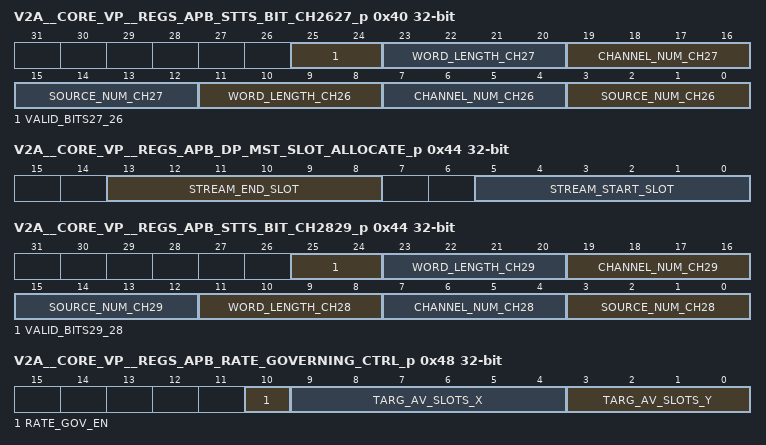
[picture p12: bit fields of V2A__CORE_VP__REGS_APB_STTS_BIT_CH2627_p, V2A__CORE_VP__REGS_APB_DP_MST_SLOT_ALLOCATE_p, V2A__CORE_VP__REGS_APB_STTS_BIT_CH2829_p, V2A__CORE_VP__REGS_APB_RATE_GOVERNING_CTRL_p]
0x40 V2A__CORE_VP__REGS_APB_STTS_BIT_CH2627_p
  [25:24] VALID_BITS27_26 rw — Valid Bits for channel 27 and 26 if force is enabled
  [23:20] WORD_LENGTH_CH27 rw — Channel 27 word length.
  [19:16] CHANNEL_NUM_CH27 rw — Channel 27 channel number.
  [15:12] SOURCE_NUM_CH27 rw — Channel 27 Source number.
  [11:8] WORD_LENGTH_CH26 rw — Channel 26 word length.
  [7:4] CHANNEL_NUM_CH26 rw — Channel 26 channel number.
  [3:0] SOURCE_NUM_CH26 rw — Channel 26 Source number.
{0x44+4i} V2A__CORE_VP__REGS_APB_SW_EVENTS{i}_p (i=0..3)
  [7:0] SW_EVENTS{8i+7}_{8i} ro — Each bit represents a separate event reported by the internal uCPU. If bit is set to 1 event is reported. All events are cleared upon read. Detailed description in Cadence HD Display TX Controller Programming Interface document.
0x44 V2A__CORE_VP__REGS_APB_DP_MST_SLOT_ALLOCATE_p
  [13:8] STREAM_END_SLOT rw — Stream end slot. This value determines last slot in MTP assigned to a given stream. Allowed values are stream_start_slot-63.
  [5:0] STREAM_START_SLOT rw — Stream start slot. This value determines first slot in MTP assigned to a given stream. Allowed values are 1-63.
0x44 V2A__CORE_VP__REGS_APB_STTS_BIT_CH2829_p
  [25:24] VALID_BITS29_28 rw — Valid Bits for channel 29 and 28 if force is enabled
  [23:20] WORD_LENGTH_CH29 rw — Channel 29 word length.
  [19:16] CHANNEL_NUM_CH29 rw — Channel 29 channel number.
  [15:12] SOURCE_NUM_CH29 rw — Channel 29 Source number.
  [11:8] WORD_LENGTH_CH28 rw — Channel 28 word length.
  [7:4] CHANNEL_NUM_CH28 rw — Channel 28 channel number.
  [3:0] SOURCE_NUM_CH28 rw — Channel 28 Source number.
0x48 V2A__CORE_VP__REGS_APB_RATE_GOVERNING_CTRL_p
  [10] RATE_GOV_EN rw — Enable rate governing. When set to 0, this stream will only output VCPF
  [9:4] TARG_AV_SLOTS_X rw — Target average number of slots per MTP configuration
  [3:0] TARG_AV_SLOTS_Y rw — Target average number of slots per MTP configuration. Fractional component
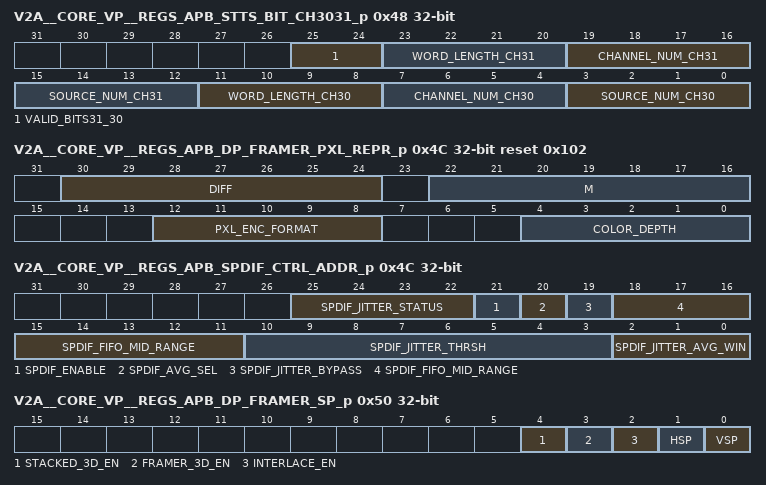
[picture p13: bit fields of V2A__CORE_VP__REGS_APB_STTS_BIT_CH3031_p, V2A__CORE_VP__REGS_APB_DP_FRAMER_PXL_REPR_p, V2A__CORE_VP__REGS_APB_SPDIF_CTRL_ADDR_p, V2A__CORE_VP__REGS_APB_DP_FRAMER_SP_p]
0x48 V2A__CORE_VP__REGS_APB_STTS_BIT_CH3031_p
  [25:24] VALID_BITS31_30 rw — Valid Bits for channel 31 and 30 if force is enabled
  [23:20] WORD_LENGTH_CH31 rw — Channel 31 word length.
  [19:16] CHANNEL_NUM_CH31 rw — Channel 31 channel number.
  [15:12] SOURCE_NUM_CH31 rw — Channel 31 Source number.
  [11:8] WORD_LENGTH_CH30 rw — Channel 30 word length.
  [7:4] CHANNEL_NUM_CH30 rw — Channel 30 channel number.
  [3:0] SOURCE_NUM_CH30 rw — Channel 30 Source number.
0x4C V2A__CORE_VP__REGS_APB_DP_FRAMER_PXL_REPR_p reset 0x102
  [30:24] DIFF rw — Difference between Denominator and Numerator of the ratio that describes valid symbols distribution. Example: If TU_VALID*=12.34 then DIFF=100-34=66. TU_VALID calculated according to DisplayPort specification. This setting apply only when compressed [DSC] stream is being transmitted.
  [22:16] M rw — Numerator of the ratio that describes valid symbols distribution. Example: If TU_VALID=12.34 then M=34. TU_VALID calculated according to DisplayPort specification. This setting apply only when compressed [DSC] stream is being transmitted.
  [12:8] PXL_ENC_FORMAT rw — Pixel encoding format: 1h - RGB 2h - YCbCr 4:4:4 4h - YCbCr 4:2:2 8h - Y CbCr 4:2:0 10h - Y-only All other values - RESERVED
  [4:0] COLOR_DEPTH rw — Color depth: 1h - 6 bpc, 2h - 8 bpc, 4h - 10 bpc, 8h - 12 bpc, 10h - 16 bpc, All other values - RESERVED
0x4C V2A__CORE_VP__REGS_APB_SPDIF_CTRL_ADDR_p
  [25:22] SPDIF_JITTER_STATUS ro
  [21] SPDIF_ENABLE rw
  [20] SPDIF_AVG_SEL rw — SPDIF average Select
  [19] SPDIF_JITTER_BYPASS rw
  [18:11] SPDIF_FIFO_MID_RANGE rw
  [10:3] SPDIF_JITTER_THRSH rw — SPDIF Jitter threshold
  [2:0] SPDIF_JITTER_AVG_WIN rw — Spdif Jitter AVG Window
0x50 V2A__CORE_VP__REGS_APB_DP_FRAMER_SP_p
  [4] STACKED_3D_EN rw — Unused. Kept RW for software backward compatibility.
  [3] FRAMER_3D_EN rw — 3D video enable, active high. This bit must be set when 3D Field Sequencial Stereo Format is enabled. Other 3D formats do not require setting this bit.
  [2] INTERLACE_EN rw — Interlaced video enable. Active high.
  [1] HSP rw — Video interface HSYNC polarity: 0 - active high, 1 - active low
  [0] VSP rw — Video interface VSYNC polarity: 0 - active high, 1 - active low
0x50 V2A__CORE_VP__REGS_APB_SPDIF_CH1_CS_3100_ADDR_p ro
  [31:0] SPDIF_CH1_ST_STTS_BITS3100 — SPDIF Channel 1 Status bits[31:0]
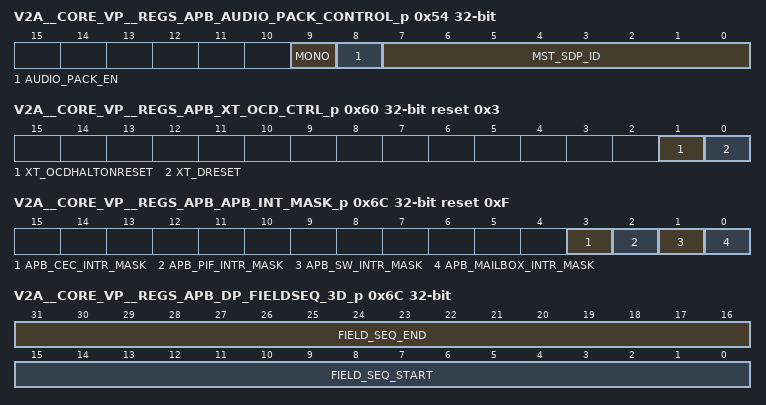
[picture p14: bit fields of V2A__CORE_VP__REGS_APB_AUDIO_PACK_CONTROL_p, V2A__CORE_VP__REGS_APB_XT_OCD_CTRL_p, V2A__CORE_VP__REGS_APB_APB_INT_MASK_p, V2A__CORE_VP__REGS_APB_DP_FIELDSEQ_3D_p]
0x54 V2A__CORE_VP__REGS_APB_AUDIO_PACK_CONTROL_p
  [9] MONO rw — In case of 2-channel layout and one lane configuration SW decides whether it is a stereo or mono transfer. Relevant for SDP HB3[2:0] - ChannelCount field
  [8] AUDIO_PACK_EN rw — Enables the Audio_Pack module, active high
  [7:0] MST_SDP_ID rw — Secondary-Data Packet ID. This field is transmitted in HB0 of the Audio SDP [Audio_TimeStamp and Audio_Stream].
0x54 V2A__CORE_VP__REGS_APB_SPDIF_CH1_CS_6332_ADDR_p ro
  [31:0] SPDIF_CH1_ST_STTS_BITS6332 — SPDIF Channel 1 Status bits[63:32]
0x58 V2A__CORE_VP__REGS_APB_SPDIF_CH1_CS_9564_ADDR_p ro
  [31:0] SPDIF_CH1_ST_STTS_BITS9564 — SPDIF Channel 1 Status bits[95:64]
0x5C V2A__CORE_VP__REGS_APB_SPDIF_CH1_CS_12796_ADDR_p ro
  [31:0] SPDIF_CH1_ST_STTS_BITS12796 — SPDIF Channel 1 Status bits[127:96]
0x60 V2A__CORE_VP__REGS_APB_XT_OCD_CTRL_p reset 0x3
  [1] XT_OCDHALTONRESET rw — Internal CPU - Halt On Reget configuration register
  [0] XT_DRESET rw — Internal CPU - Dreset control register
0x60 V2A__CORE_VP__REGS_APB_SPDIF_CH1_CS_159128_ADDR_p ro
  [31:0] SPDIF_CH1_ST_STTS_BITS159128 — SPDIF Channel 1 Status bits[159:128]
0x64 V2A__CORE_VP__REGS_APB_XT_OCD_CTRL_RO_p
  [0] XT_XOCDMODE ro — Internal CPU - OCD mode configuration
0x64 V2A__CORE_VP__REGS_APB_LINE_THRESH_p reset 0x20
  [5:0] CFG_ACTIVE_LINE_TRESH rw — Video Fifo Latency threshold. Defines the number of FIFO rows before reading starts. This setting depends on the transmitted video format and link rate.
0x64 V2A__CORE_VP__REGS_APB_SPDIF_CH1_CS_191160_ADDR_p ro
  [31:0] SPDIF_CH1_ST_STTS_BITS191160 — SPDIF Channel 1 Status bits[191:160]
0x68 V2A__CORE_VP__REGS_APB_DP_VB_ID_p reset 0x9
  [7:0] VB_ID rw — VB-ID as described in the DisplayPort specification. Bits that are timing dependent [VerticalBlanking_Flag, FieldID_Flag, HDCP SYNC DETECT, Compressed Stream_Flag] are overriden by hardware thus actual value written to the register is ignored.
0x68 V2A__CORE_VP__REGS_APB_SPDIF_CH2_CS_3100_ADDR_p ro
  [31:0] SPDIF_CH2_ST_STTS_BITS3100 — SPDIF Channel 2 Status bits[31:0]
0x6C V2A__CORE_VP__REGS_APB_APB_INT_MASK_p reset 0xF
  [3] APB_CEC_INTR_MASK rw — Reserved field. 0x0 when read. Writes ignored.
  [2] APB_PIF_INTR_MASK rw — PIF module Interrupt mask 0x0-interrupt enabled 0x1-interrupt disabled
  [1] APB_SW_INTR_MASK rw — SW Event Interrupt mask 0x0-interrupt enabled 0x1-interrupt disabled
  [0] APB_MAILBOX_INTR_MASK rw — Mailbox Interrupt mask 0x0-interrupt enabled 0x1-interrupt disabled
0x6C V2A__CORE_VP__REGS_APB_DP_FIELDSEQ_3D_p rw
  [31:16] FIELD_SEQ_END — Number of line in the frame where the Vblank part in the field sequential format ends
  [15:0] FIELD_SEQ_START — Number of line in the frame where the Vblank part in the field sequential format starts
0x6C V2A__CORE_VP__REGS_APB_SPDIF_CH2_CS_6332_ADDR_p ro
  [31:0] SPDIF_CH2_ST_STTS_BITS6332 — SPDIF Channel 2 Status bits[63:32]
0x70 V2A__CORE_VP__REGS_APB_APB_INT_STATUS_p
  [3] APB_CEC_INTR_STATUS ro — Reserved.
  [2] APB_PIF_INTR_STATUS ro — PIF module Interrupt status. Active HIGH. If this bit is set further status should be read from SOURCE_PIF_INTERRUPT_SOURCE register. This bit is cleared automatically on read from SOURCE_PIF_INTERRUPT_SOURCE register.
  [1] APB_SW_INTR_STATUS ro — SW Events Interrupt status. Active HIGH. If this bit is set further status should be read from SW_EVENTSn registers. This bit is cleared automatically on read from SW_EVENTSn registers if there are no more events.
  [0] APB_MAILBOX_INTR_STATUS ro — Mailbox Interrupt status. Active HIGH. If this bit is set further status should be read from MAILBOX_INT_STATUS register. This bit is cleared automatically on read from MAILBOX_INT_STATUS register.
0x70 V2A__CORE_VP__REGS_APB_SPDIF_CH2_CS_9564_ADDR_p ro
  [31:0] SPDIF_CH2_ST_STTS_BITS9564 — SPDIF Channel 2 Status bits[95:64]
0x74 V2A__CORE_VP__REGS_APB_SPDIF_CH2_CS_12796_ADDR_p ro
  [31:0] SPDIF_CH2_ST_STTS_BITS12796 — SPDIF Channel 2 Status bits[127:96]
0x78 V2A__CORE_VP__REGS_APB_DP_FRONT_BACK_PORCH_p rw reset 0x10003C
  [31:16] FRONT_PORCH — Value of the front porch
  [15:0] BACK_PORCH — Value of the back porch
0x78 V2A__CORE_VP__REGS_APB_SPDIF_CH2_CS_159128_ADDR_p ro
  [31:0] SPDIF_CH2_ST_STTS_BITS159128 — SPDIF Channel 2 Status bits[159:128]
0x7C V2A__CORE_VP__REGS_APB_DP_BYTE_COUNT_p rw reset 0x2A4
  [31:16] BYTES_IN_CHUNK — Number of bytes in chunk per lane, including additional EOC symbol.
  [15:0] BYTE_COUNT — Total number of bytes in a line in case of non-DSC video. When DSC is enabled should be total number of bytes in a line *per lane*, including the additional EOC symbol[s].
0x7C V2A__CORE_VP__REGS_APB_SPDIF_CH2_CS_191160_ADDR_p ro
  [31:0] SPDIF_CH2_ST_STTS_BITS191160 — SPDIF Channel 2 Status bits[191:160]
